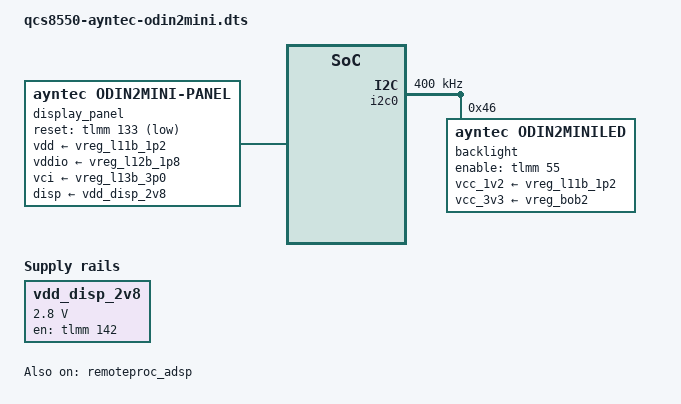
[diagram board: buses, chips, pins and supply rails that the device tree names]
// SPDX-License-Identifier: BSD-3-Clause
/*
 * Copyright (c) 2025, Teguh Sobirin.
 */

/dts-v1/;

#include <dt-bindings/gpio/gpio.h>
#include <dt-bindings/interrupt-controller/irq.h>
#include "qcs8550-ayntec-common.dtsi"

&{/} {
	model = "AYN Odin 2 Mini";
	compatible = "ayntec,odin2mini", "qcom,qcs8550", "qcom,sm8550";

	vdd_disp_2v8: vdd-disp-2v8-regulator {
		compatible = "regulator-fixed";
		regulator-name = "vdd_disp_2v8";

		regulator-min-microvolt = <2800000>;
		regulator-max-microvolt = <2800000>;

		gpio = <&tlmm 142 GPIO_ACTIVE_HIGH>;
		enable-active-high;
	};
};

&display_panel {
	compatible = "ayntec,odin2mini-panel";

	pinctrl-0 = <&dsi_p_rst_active>, <&dsi_p_te_active>;
	pinctrl-1 = <&dsi_p_rst_suspend>, <&dsi_p_te_suspend>;
	pinctrl-names = "default", "sleep";

	vdd-supply = <&vreg_l11b_1p2>;
	vddio-supply = <&vreg_l12b_1p8>;
	vci-supply = <&vreg_l13b_3p0>;
	disp-supply = <&vdd_disp_2v8>;

	reset-gpios = <&tlmm 133 GPIO_ACTIVE_LOW>;

	rotation = <90>;
};

&i2c0 {
	clock-frequency = <400000>;

	status = "okay";

	#address-cells = <1>;
	#size-cells = <0>;

	backlight: backlight@46 {
		compatible = "ayntec,odin2miniled";
		reg = <0x46>;
		enable-gpios = <&tlmm 55 GPIO_ACTIVE_HIGH>;
		vcc_1v2-supply = <&vreg_l11b_1p2>;
		vcc_3v3-supply = <&vreg_bob2>;
	};
};

/* There is an hdmi bridge on i2c_hub_0@48, but it is not currently supported */

&remoteproc_adsp {
	firmware-name = "qcom/sm8550/ayntec/odin2mini/adsp.mbn",
			"qcom/sm8550/ayntec/odin2mini/adsp_dtb.mbn";

	status = "okay";
};

&spk_amp_l {
	firmware-name = "qcom/sm8550/ayntec/odin2mini/aw883xx_acf.bin";
};

&spk_amp_r {
	firmware-name = "qcom/sm8550/ayntec/odin2mini/aw883xx_acf.bin";
};

